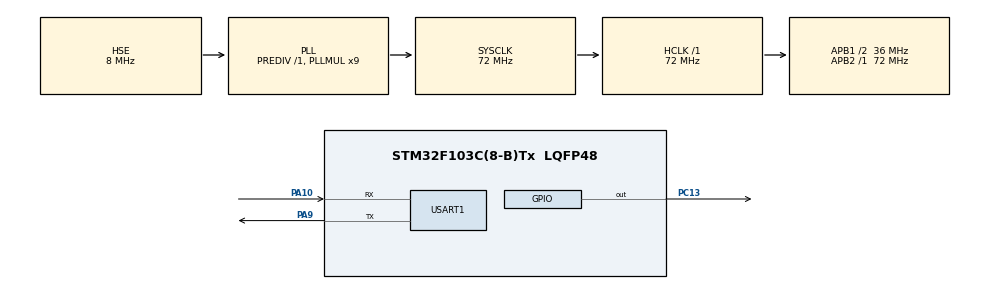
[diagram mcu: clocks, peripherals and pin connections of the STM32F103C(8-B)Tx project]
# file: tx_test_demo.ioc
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Dma.Request0=USART1_RX
Dma.Request1=USART1_TX
Dma.USART1_RX.0.Direction=DMA_PERIPH_TO_MEMORY
Dma.USART1_RX.0.Instance=DMA1_Channel5
Dma.USART1_RX.0.MemDataAlignment=DMA_MDATAALIGN_BYTE
Dma.USART1_RX.0.MemInc=DMA_MINC_ENABLE
Dma.USART1_RX.0.Mode=DMA_NORMAL
Dma.USART1_RX.0.PeriphDataAlignment=DMA_PDATAALIGN_BYTE
Dma.USART1_RX.0.PeriphInc=DMA_PINC_DISABLE
Dma.USART1_RX.0.Priority=DMA_PRIORITY_LOW
Dma.USART1_TX.1.Direction=DMA_MEMORY_TO_PERIPH
Dma.USART1_TX.1.Instance=DMA1_Channel4
Dma.USART1_TX.1.MemDataAlignment=DMA_MDATAALIGN_BYTE
Dma.USART1_TX.1.MemInc=DMA_MINC_ENABLE
Dma.USART1_TX.1.Mode=DMA_NORMAL
Dma.USART1_TX.1.PeriphDataAlignment=DMA_PDATAALIGN_BYTE
Dma.USART1_TX.1.PeriphInc=DMA_PINC_DISABLE
Dma.USART1_TX.1.Priority=DMA_PRIORITY_LOW
Mcu.Family=STM32F1
Mcu.Name=STM32F103C(8-B)Tx
Mcu.Package=LQFP48
NVIC.DMA1_Channel4_IRQn=true\:0\:0\:false\:false\:true\:false\:true\:true
NVIC.DMA1_Channel5_IRQn=true\:0\:0\:false\:false\:true\:false\:true\:true
NVIC.PriorityGroup=NVIC_PRIORITYGROUP_4
NVIC.TIM1_UP_IRQn=true\:0\:0\:false\:false\:true\:true\:true\:true
NVIC.USART1_IRQn=true\:5\:0\:true\:false\:true\:true\:true\:true
PA10.Mode=Asynchronous
PA10.Signal=USART1_RX
PA13.Mode=Serial_Wire
PA13.Signal=SYS_JTMS-SWDIO
PA14.Mode=Serial_Wire
PA14.Signal=SYS_JTCK-SWCLK
PA9.Mode=Asynchronous
PA9.Signal=USART1_TX
PC13-TAMPER-RTC.GPIO_ModeDefaultOutputPP=GPIO_MODE_OUTPUT_PP
PC13-TAMPER-RTC.GPIO_PuPd=GPIO_NOPULL
PC13-TAMPER-RTC.GPIO_Speed=GPIO_SPEED_FREQ_LOW
PC13-TAMPER-RTC.PinState=GPIO_PIN_SET
PC13-TAMPER-RTC.Signal=GPIO_Output
PD0-OSC_IN.Mode=HSE-External-Oscillator
PD0-OSC_IN.Signal=RCC_OSC_IN
PD1-OSC_OUT.Mode=HSE-External-Oscillator
PD1-OSC_OUT.Signal=RCC_OSC_OUT
ProjectManager.HeapSize=0x200
ProjectManager.StackSize=0x400
ProjectManager.TargetToolchain=MDK-ARM V5.32
RCC.AHBFreq_Value=72000000
RCC.APB1CLKDivider=RCC_HCLK_DIV2
RCC.APB1Freq_Value=36000000
RCC.APB1TimFreq_Value=72000000
RCC.APB2Freq_Value=72000000
RCC.APB2TimFreq_Value=72000000
RCC.HCLKFreq_Value=72000000
RCC.PLLMUL=RCC_PLL_MUL9
RCC.PLLSourceVirtual=RCC_PLLSOURCE_HSE
RCC.SYSCLKFreq_VALUE=72000000
RCC.SYSCLKSource=RCC_SYSCLKSOURCE_PLLCLK
RCC.USBFreq_Value=72000000
TIM1.Period=249
TIM1.Prescaler=7200-1
USART1.VirtualMode=VM_ASYNC
VP_TIM1_VS_ClockSourceINT.Mode=Internal
board=custom

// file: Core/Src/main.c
/* USER CODE BEGIN Header */
/**
  ******************************************************************************
  * @file           : main.c
  * @brief          : Main program body
  ******************************************************************************
  * @attention
  *
  * Copyright (c) 2026 STMicroelectronics.
  * All rights reserved.
  *
  * This software is licensed under terms that can be found in the LICENSE file
  * in the root directory of this software component.
  * If no LICENSE file comes with this software, it is provided AS-IS.
  *
  ******************************************************************************
  */
/* USER CODE END Header */
#include "main.h"
#include "dma.h"
#include "tim.h"
#include "usart.h"
#include "gpio.h"

/* USER CODE BEGIN Includes */
#define RX_BUF_SIZE 128

uint8_t rx_buffer[RX_BUF_SIZE];
uint16_t rx_len = 0;          // �ĳ�16λ����ȫ
uint8_t rx_flag = 0;
uint32_t time_use=0;
uint32_t time_start = 0;
uint8_t tx_buf[25] ={0x01,0x02,0x03,0x04,0x05};
uint16_t tx_cnt=0;
/* USER CODE END Includes */

void SystemClock_Config(void);

int main(void)
{

  /* MCU Configuration--------------------------------------------------------*/

  /* Reset of all peripherals, Initializes the Flash interface and the Systick. */
  HAL_Init();

  /* Configure the system clock */
  SystemClock_Config();

  /* Initialize all configured peripherals */
  MX_GPIO_Init();
  MX_DMA_Init();
  MX_USART1_UART_Init();
  MX_TIM1_Init();
  /* USER CODE BEGIN 2 */
  HAL_UARTEx_ReceiveToIdle_DMA(&huart1, rx_buffer, RX_BUF_SIZE);

	HAL_TIM_Base_Start_IT(&htim1);
//  HAL_UART_Transmit(&huart1, tx_buf, sizeof(tx_buf), 100);

  time_start = HAL_GetTick();  // ��¼����ʱ��
  /* USER CODE END 2 */

  /* Infinite loop */
  while (1)
  {

    /* USER CODE BEGIN 3 */
		if(rx_flag==1)
		{
//			time_use=HAL_GetTick()-time_start;
//			time_start=HAL_GetTick();
			HAL_GPIO_WritePin(GPIOC, GPIO_PIN_13, GPIO_PIN_RESET);
			rx_flag=0;
			rx_len=0;
		}

  }
  /* USER CODE END 3 */
}

void SystemClock_Config(void)
{
  RCC_OscInitTypeDef RCC_OscInitStruct = {0};
  RCC_ClkInitTypeDef RCC_ClkInitStruct = {0};

  /** Initializes the RCC Oscillators according to the specified parameters
  * in the RCC_OscInitTypeDef structure.
  */
  RCC_OscInitStruct.OscillatorType = RCC_OSCILLATORTYPE_HSE;
  RCC_OscInitStruct.HSEState = RCC_HSE_ON;
  RCC_OscInitStruct.HSEPredivValue = RCC_HSE_PREDIV_DIV1;
  RCC_OscInitStruct.HSIState = RCC_HSI_ON;
  RCC_OscInitStruct.PLL.PLLState = RCC_PLL_ON;
  RCC_OscInitStruct.PLL.PLLSource = RCC_PLLSOURCE_HSE;
  RCC_OscInitStruct.PLL.PLLMUL = RCC_PLL_MUL9;
  if (HAL_RCC_OscConfig(&RCC_OscInitStruct) != HAL_OK)
  {
    Error_Handler();
  }

  /** Initializes the CPU, AHB and APB buses clocks
  */
  RCC_ClkInitStruct.ClockType = RCC_CLOCKTYPE_HCLK|RCC_CLOCKTYPE_SYSCLK
                              |RCC_CLOCKTYPE_PCLK1|RCC_CLOCKTYPE_PCLK2;
  RCC_ClkInitStruct.SYSCLKSource = RCC_SYSCLKSOURCE_PLLCLK;
  RCC_ClkInitStruct.AHBCLKDivider = RCC_SYSCLK_DIV1;
  RCC_ClkInitStruct.APB1CLKDivider = RCC_HCLK_DIV2;
  RCC_ClkInitStruct.APB2CLKDivider = RCC_HCLK_DIV1;

  if (HAL_RCC_ClockConfig(&RCC_ClkInitStruct, FLASH_LATENCY_2) != HAL_OK)
  {
    Error_Handler();
  }
}

/* USER CODE BEGIN 4 */

void HAL_UARTEx_RxEventCallback(UART_HandleTypeDef *huart_, uint16_t size_)
{
    rx_len = size_;
    rx_flag = 1;
		if(rx_buffer[0]==0x05&&rx_buffer[1]==0x04&&rx_buffer[2]==0x03&&rx_buffer[3]==0x02&&rx_buffer[4]==0x01)
		{
			tx_cnt=1000;
		}
}

void HAL_UART_ErrorCallback(UART_HandleTypeDef *huart)
{
	 HAL_UARTEx_ReceiveToIdle_DMA(&huart1, rx_buffer, RX_BUF_SIZE);
}

void HAL_TIM_PeriodElapsedCallback(TIM_HandleTypeDef *htim)
{
    if (htim->Instance == TIM1)  // 注意是TIM1，不是TIM2
    {
			if(tx_cnt>0)
			{
				HAL_UART_Transmit_DMA(&huart1, tx_buf, sizeof(tx_buf));
				tx_cnt--;
			}else 	HAL_GPIO_WritePin(GPIOC, GPIO_PIN_13, GPIO_PIN_SET);
    }
}

/* USER CODE END 4 */

void Error_Handler(void)
{
  __disable_irq();
  while (1)
  {
  }
}
